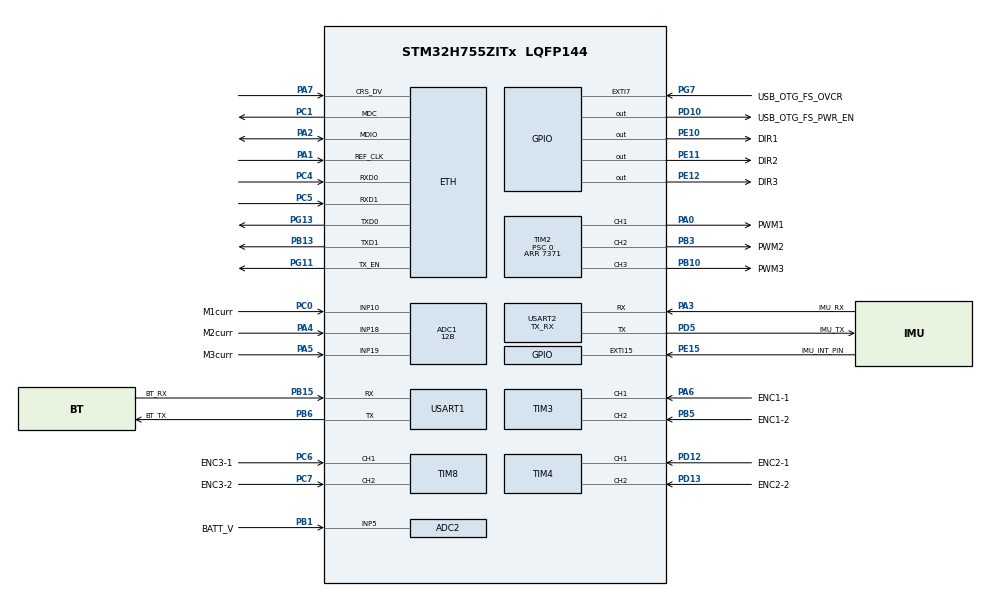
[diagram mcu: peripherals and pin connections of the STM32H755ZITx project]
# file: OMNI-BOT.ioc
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ADC1.Channel-1\#ChannelRegularConversion=ADC_CHANNEL_10
ADC1.Channel-2\#ChannelRegularConversion=ADC_CHANNEL_18
ADC1.Channel-3\#ChannelRegularConversion=ADC_CHANNEL_19
ADC1.ContinuousConvMode=DISABLE
ADC1.ExternalTrigConv=ADC_EXTERNALTRIG_T6_TRGO
ADC1.NbrOfConversion=3
ADC1.NbrOfConversionFlag=1
ADC1.OffsetNumber-1\#ChannelRegularConversion=ADC_OFFSET_NONE
ADC1.OffsetNumber-2\#ChannelRegularConversion=ADC_OFFSET_NONE
ADC1.OffsetNumber-3\#ChannelRegularConversion=ADC_OFFSET_NONE
ADC1.OffsetSignedSaturation-1\#ChannelRegularConversion=DISABLE
ADC1.OffsetSignedSaturation-2\#ChannelRegularConversion=DISABLE
ADC1.OffsetSignedSaturation-3\#ChannelRegularConversion=DISABLE
ADC1.Overrun=ADC_OVR_DATA_OVERWRITTEN
ADC1.Rank-1\#ChannelRegularConversion=1
ADC1.Rank-2\#ChannelRegularConversion=2
ADC1.Rank-3\#ChannelRegularConversion=3
ADC1.Resolution=ADC_RESOLUTION_12B
ADC1.SamplingTime-1\#ChannelRegularConversion=ADC_SAMPLETIME_64CYCLES_5
ADC1.SamplingTime-2\#ChannelRegularConversion=ADC_SAMPLETIME_64CYCLES_5
ADC1.SamplingTime-3\#ChannelRegularConversion=ADC_SAMPLETIME_64CYCLES_5
ADC1.master=1
ADC2.Channel-1\#ChannelRegularConversion=ADC_CHANNEL_5
ADC2.NbrOfConversionFlag=1
ADC2.OffsetNumber-1\#ChannelRegularConversion=ADC_OFFSET_NONE
ADC2.OffsetSignedSaturation-1\#ChannelRegularConversion=DISABLE
ADC2.Rank-1\#ChannelRegularConversion=1
ADC2.SamplingTime-1\#ChannelRegularConversion=ADC_SAMPLETIME_64CYCLES_5
CortexM4.IPs=FATFS_M4\:I,FREERTOS_M4\:I,IWDG2\:I,RCC,WWDG2\:I,DMA,BDMA,MDMA,NVIC2\:I,ETH,USART3,DEBUG,PDM2PCM_M4\:I,PWR,RESMGR_UTILITY,SYS_M4\:I,USB_DEVICE_M4\:I,USB_HOST_M4\:I,CORTEX_M4\:I,GPIO,OPENAMP_M4\:I,VREFBUF,NUCLEO-H755ZI-Q
CortexM7.IPs=FATFS_M7\:I,FREERTOS_M7\:I,IWDG1\:I,RCC\:I,WWDG1\:I,DMA\:I,BDMA\:I,MDMA\:I,NVIC1\:I,ETH\:I,USART3\:I,USB_OTG_FS\:I,SYS\:I,CORTEX_M7\:I,DEBUG\:I,PDM2PCM_M7\:I,PWR\:I,RESMGR_UTILITY\:I,USB_DEVICE_M7\:I,USB_HOST_M7\:I,GPIO\:I,OPENAMP_M7\:I,VREFBUF\:I,NUCLEO-H755ZI-Q\:I,TIM2\:I,TIM8\:I,TIM3\:I,TIM4\:I,USART2\:I,USART1\:I,LWIP\:I,ADC1\:I,ADC2\:I
CortexM7.Pins=PE15
Dma.ADC1.0.Direction=DMA_PERIPH_TO_MEMORY
Dma.ADC1.0.EventEnable=DISABLE
Dma.ADC1.0.FIFOMode=DMA_FIFOMODE_DISABLE
Dma.ADC1.0.Instance=DMA1_Stream0
Dma.ADC1.0.MemDataAlignment=DMA_MDATAALIGN_HALFWORD
Dma.ADC1.0.MemInc=DMA_MINC_ENABLE
Dma.ADC1.0.Mode=DMA_CIRCULAR
Dma.ADC1.0.PeriphDataAlignment=DMA_PDATAALIGN_HALFWORD
Dma.ADC1.0.PeriphInc=DMA_PINC_DISABLE
Dma.ADC1.0.Polarity=HAL_DMAMUX_REQ_GEN_RISING
Dma.ADC1.0.Priority=DMA_PRIORITY_LOW
Dma.ADC1.0.RequestNumber=1
Dma.ADC1.0.SignalID=NONE
Dma.ADC1.0.SyncEnable=DISABLE
Dma.ADC1.0.SyncPolarity=HAL_DMAMUX_SYNC_NO_EVENT
Dma.ADC1.0.SyncRequestNumber=1
Dma.ADC1.0.SyncSignalID=NONE
Dma.Request0=ADC1
ETH.MediaInterface=HAL_ETH_RMII_MODE
FREERTOS_M4.Tasks01=defaultTask,24,128,StartDefaultTask,Default,NULL,Dynamic,NULL,NULL
FREERTOS_M4.configENABLE_FPU=1
FREERTOS_M7.Tasks01=defaultTask,24,1024,StartDefaultTask,Default,NULL,Dynamic,NULL,NULL
FREERTOS_M7.configENABLE_FPU=1
FREERTOS_M7.configTOTAL_HEAP_SIZE=98304
LWIP.BSP.number=1
LWIP.GATEWAY_ADDRESS=192.168.001.001
LWIP.IP_ADDRESS=192.168.001.010
LWIP.LWIP_DHCP=0
LWIP.LWIP_TCP=0
LWIP.NETMASK_ADDRESS=255.255.255.000
LWIP.Version=v2.1.2_Cube
LWIP0.BSP.STBoard=false
LWIP0.BSP.api=BSP_COMPONENT_DRIVER
LWIP0.BSP.component=LAN8742
LWIP0.BSP.instance=LAN8742
LWIP0.BSP.name=Driver_PHY
LWIP0.BSP.semaphore=S_LAN8742
LWIP0.BSP.solution=LAN8742
Mcu.Family=STM32H7
Mcu.Name=STM32H755ZITx
Mcu.Package=LQFP144
NUCLEO-H755ZI-Q.BUTTON=1
NUCLEO-H755ZI-Q.LD1=true
NUCLEO-H755ZI-Q.LD2=true
NUCLEO-H755ZI-Q.LD3=true
NUCLEO-H755ZI-Q.VCP=true
NVIC1.DMA1_Stream0_IRQn=true\:5\:0\:false\:false\:true\:true\:false\:true\:true
NVIC1.ETH_IRQn=true\:5\:0\:false\:false\:true\:true\:true\:true\:true
NVIC1.EXTI15_10_IRQn=true\:5\:0\:false\:false\:true\:true\:false\:true\:true
NVIC1.PriorityGroup=NVIC_PRIORITYGROUP_4
NVIC1.USART1_IRQn=true\:5\:0\:false\:false\:true\:true\:true\:true\:true
NVIC1.USART2_IRQn=true\:5\:0\:false\:false\:true\:true\:true\:true\:true
NVIC2.PriorityGroup=NVIC_PRIORITYGROUP_4
PA0.GPIO_Label=PWM1
PA0.PinAttribute=CortexM7
PA0.Signal=S_TIM2_CH1_ETR
PA1.Mode=RMII
PA1.PinAttribute=CortexM7
PA1.Signal=ETH_REF_CLK
PA11.PinAttribute=CortexM7
PA11.Signal=USB_OTG_FS_DM
PA12.PinAttribute=CortexM7
PA12.Signal=USB_OTG_FS_DP
PA2.Mode=RMII
PA2.PinAttribute=CortexM7
PA2.Signal=ETH_MDIO
PA3.GPIO_Label=IMU_RX
PA3.Mode=Asynchronous
PA3.PinAttribute=CortexM7
PA3.Signal=USART2_RX
PA4.GPIO_Label=M2curr
PA4.PinAttribute=CortexM7
PA4.Signal=ADCx_INP18
PA5.GPIO_Label=M3curr
PA5.PinAttribute=CortexM7
PA5.Signal=ADCx_INP19
PA6.GPIO_Label=ENC1-1
PA6.PinAttribute=CortexM7
PA6.Signal=S_TIM3_CH1
PA7.Mode=RMII
PA7.PinAttribute=CortexM7
PA7.Signal=ETH_CRS_DV
PA8.PinAttribute=CortexM7
PA8.Signal=USB_OTG_FS_SOF
PA9.PinAttribute=CortexM7
PA9.Signal=USB_OTG_FS_VBUS
PB1.GPIO_Label=BATT_V
PB1.PinAttribute=CortexM7
PB1.Signal=ADCx_INP5
PB10.GPIO_Label=PWM3
PB10.PinAttribute=CortexM7
PB10.Signal=S_TIM2_CH3
PB13.Mode=RMII
PB13.PinAttribute=CortexM7
PB13.Signal=ETH_TXD1
PB15.GPIO_Label=BT_RX
PB15.Mode=Asynchronous
PB15.PinAttribute=CortexM7
PB15.Signal=USART1_RX
PB3\ (JTDO/TRACESWO).GPIO_Label=PWM2
PB3\ (JTDO/TRACESWO).PinAttribute=CortexM7
PB3\ (JTDO/TRACESWO).Signal=S_TIM2_CH2
PB5.GPIO_Label=ENC1-2
PB5.PinAttribute=CortexM7
PB5.Signal=S_TIM3_CH2
PB6.GPIO_Label=BT_TX
PB6.Mode=Asynchronous
PB6.PinAttribute=CortexM7
PB6.Signal=USART1_TX
PC0.GPIO_Label=M1curr
PC0.PinAttribute=CortexM7
PC0.Signal=ADCx_INP10
PC1.Mode=RMII
PC1.PinAttribute=CortexM7
PC1.Signal=ETH_MDC
PC14-OSC32_IN\ (OSC32_IN).PinAttribute=Free
PC14-OSC32_IN\ (OSC32_IN).Signal=RCC_OSC32_IN
PC15-OSC32_OUT\ (OSC32_OUT).PinAttribute=Free
PC15-OSC32_OUT\ (OSC32_OUT).Signal=RCC_OSC32_OUT
PC4.Mode=RMII
PC4.PinAttribute=CortexM7
PC4.Signal=ETH_RXD0
PC5.Mode=RMII
PC5.PinAttribute=CortexM7
PC5.Signal=ETH_RXD1
PC6.GPIO_Label=ENC3-1
PC6.PinAttribute=CortexM7
PC6.Signal=S_TIM8_CH1
PC7.GPIO_Label=ENC3-2
PC7.PinAttribute=CortexM7
PC7.Signal=S_TIM8_CH2
PD10.GPIO_Label=USB_OTG_FS_PWR_EN
PD10.PinAttribute=Free
PD10.Signal=GPIO_Output
PD12.GPIO_Label=ENC2-1
PD12.PinAttribute=CortexM7
PD12.Signal=S_TIM4_CH1
PD13.GPIO_Label=ENC2-2
PD13.PinAttribute=CortexM7
PD13.Signal=S_TIM4_CH2
PD5.GPIO_Label=IMU_TX
PD5.Mode=Asynchronous
PD5.PinAttribute=CortexM7
PD5.Signal=USART2_TX
PD8.Signal=USART3_TX
PD9.Signal=USART3_RX
PE10.GPIO_Label=DIR1
PE10.PinAttribute=Free
PE10.Signal=GPIO_Output
PE11.GPIO_Label=DIR2
PE11.PinAttribute=Free
PE11.Signal=GPIO_Output
PE12.GPIO_Label=DIR3
PE12.PinAttribute=Free
PE12.Signal=GPIO_Output
PE15.GPIO_Label=IMU_INT_PIN
PE15.GPIO_ModeDefaultEXTI=GPIO_MODE_IT_FALLING
PE15.GPIO_PuPd=GPIO_PULLUP
PE15.PinAttribute=CortexM7
PE15.Signal=GPXTI15
PG11.Mode=RMII
PG11.PinAttribute=CortexM7
PG11.Signal=ETH_TX_EN
PG13.Mode=RMII
PG13.PinAttribute=CortexM7
PG13.Signal=ETH_TXD0
PG7.GPIO_Label=USB_OTG_FS_OVCR
PG7.PinAttribute=Free
PG7.Signal=GPXTI7
PH0-OSC_IN\ (PH0).PinAttribute=Free
PH0-OSC_IN\ (PH0).Signal=RCC_OSC_IN
PH1-OSC_OUT\ (PH1).PinAttribute=Free
PH1-OSC_OUT\ (PH1).Signal=RCC_OSC_OUT
ProjectManager.HeapSize=M4-0x200,M7-0x200
ProjectManager.StackSize=M4-0x400,M7-0x400
ProjectManager.TargetToolchain=Makefile
RCC.ADCCLockSelection=RCC_ADCCLKSOURCE_CLKP
RCC.ADCFreq_Value=64000000
RCC.APB1Freq_Value=73600000
RCC.APB2Freq_Value=73600000
RCC.APB3Freq_Value=73600000
RCC.APB4Freq_Value=73600000
RCC.CortexFreq_Value=294400000
RCC.D1PPRE=RCC_APB3_DIV2
RCC.D2PPRE1=RCC_APB1_DIV2
RCC.D2PPRE2=RCC_APB2_DIV2
RCC.D3PPRE=RCC_APB4_DIV2
RCC.DIVM1=5
RCC.DIVN1=46
RCC.DIVQ1=5
RCC.HCLKFreq_Value=147200000
RCC.HPRE=RCC_HCLK_DIV2
RCC.SYSCLKFreq_VALUE=294400000
RCC.SYSCLKSource=RCC_SYSCLKSOURCE_PLLCLK
RCC.SupplySource=PWR_DIRECT_SMPS_SUPPLY
RCC.USBFreq_Value=117760000
SH.ADCx_INP10.0=ADC1_INP10,IN10-Single-Ended
SH.ADCx_INP18.0=ADC1_INP18,IN18-Single-Ended
SH.ADCx_INP19.0=ADC1_INP19,IN19-Single-Ended
SH.ADCx_INP5.0=ADC2_INP5,IN5-Single-Ended
SH.S_TIM2_CH1_ETR.0=TIM2_CH1,PWM Generation1 CH1
SH.S_TIM2_CH2.0=TIM2_CH2,PWM Generation2 CH2
SH.S_TIM2_CH3.0=TIM2_CH3,PWM Generation3 CH3
SH.S_TIM3_CH1.0=TIM3_CH1,Encoder_Interface
SH.S_TIM3_CH2.0=TIM3_CH2,Encoder_Interface
SH.S_TIM4_CH1.0=TIM4_CH1,Encoder_Interface
SH.S_TIM4_CH2.0=TIM4_CH2,Encoder_Interface
SH.S_TIM8_CH1.0=TIM8_CH1,Encoder_Interface
SH.S_TIM8_CH2.0=TIM8_CH2,Encoder_Interface
TIM2.AutoReloadPreload=TIM_AUTORELOAD_PRELOAD_ENABLE
TIM2.Channel-PWM\ Generation1\ CH1=TIM_CHANNEL_1
TIM2.Channel-PWM\ Generation2\ CH2=TIM_CHANNEL_2
TIM2.Channel-PWM\ Generation3\ CH3=TIM_CHANNEL_3
TIM2.Period=7371
TIM2.Prescaler=0
TIM3.EncoderMode=TIM_ENCODERMODE_TI12
TIM3.IC1Filter=8
TIM3.IC2Filter=8
TIM4.EncoderMode=TIM_ENCODERMODE_TI12
TIM4.IC1Filter=8
TIM4.IC2Filter=8
TIM8.EncoderMode=TIM_ENCODERMODE_TI12
TIM8.IC1Filter=8
TIM8.IC2Filter=8
USART1.VirtualMode-Asynchronous=VM_ASYNC
USART2.Mode=MODE_TX_RX
USART2.VirtualMode-Asynchronous=VM_ASYNC
VP_FREERTOS_M4_VS_CMSIS_V2.Mode=CMSIS_V2
VP_FREERTOS_M7_VS_CMSIS_V2.Mode=CMSIS_V2
VP_LWIP_VS_Enabled.Mode=Enabled
VP_NUCLEO-H755ZI-Q_VS_BSP_COMMON.Mode=COMMON
VP_SYS_M4_VS_Systick.Mode=SysTick
board=NUCLEO-H755ZI-Q

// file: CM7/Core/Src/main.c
/* USER CODE BEGIN Header */
/**
  ******************************************************************************
  * @file           : main.c
  * @brief          : Main program body
  ******************************************************************************
  * @attention
  *
  * Copyright (c) 2025 STMicroelectronics.
  * All rights reserved.
  *
  * This software is licensed under terms that can be found in the LICENSE file
  * in the root directory of this software component.
  * If no LICENSE file comes with this software, it is provided AS-IS.
  *
  ******************************************************************************
  */
/* USER CODE END Header */
#include "main.h"
#include "cmsis_os.h"
#include "lwip.h"

/* USER CODE BEGIN Includes */
#include "controller.h"
#include "sensor.h"
#include <stdio.h>
#include "cmd.h"
#include "IMU.h"
#include "udp_client.h"
#include "battery_monitor.h"
/* USER CODE END Includes */

/* USER CODE BEGIN PTD */
// Omni geometry (180 mm wheel diameter => 0.09 m radius)
double rw = 0.09;        // wheel radius (m)
double L = 0.2;          // distance from robot center to wheel contact line (m)
static const double CPR = SATURN5303_OUTPUT_CPR;
const int32_t CNT_MID = 32768;  // 0x8000
/* USER CODE END PTD */

/* USER CODE BEGIN PD */

/* DUAL_CORE_BOOT_SYNC_SEQUENCE: Define for dual core boot synchronization    */
/*                             demonstration code based on hardware semaphore */
/* This define is present in both CM7/CM4 projects                            */
/* To comment when developping/debugging on a single core                     */
#define DUAL_CORE_BOOT_SYNC_SEQUENCE

#if defined(DUAL_CORE_BOOT_SYNC_SEQUENCE)
#ifndef HSEM_ID_0
#define HSEM_ID_0 (0U) /* HW semaphore 0*/
#endif
#endif /* DUAL_CORE_BOOT_SYNC_SEQUENCE */

/* USER CODE END PD */

/* USER CODE BEGIN PM */
double const pion180 = 0.01745329251;
/* USER CODE END PM */

COM_InitTypeDef BspCOMInit;
ADC_HandleTypeDef hadc1;
ADC_HandleTypeDef hadc2;
DMA_HandleTypeDef hdma_adc1;

TIM_HandleTypeDef htim2;
TIM_HandleTypeDef htim3;
TIM_HandleTypeDef htim4;
TIM_HandleTypeDef htim8;

UART_HandleTypeDef huart1;
UART_HandleTypeDef huart2;

/* Definitions for defaultTask */
osThreadId_t defaultTaskHandle;
const osThreadAttr_t defaultTask_attributes = {
  .name = "defaultTask",
  .stack_size = 1024 * 4,
  .priority = (osPriority_t) osPriorityNormal,
};
/* USER CODE BEGIN PV */

static TIM_HandleTypeDef htim6;

osThreadId_t control_id;
const osThreadAttr_t control_att = {
  .name = "control_t",
  .stack_size = 1028*8,
  .priority = (osPriority_t) osPriorityNormal,
};
osThreadId_t remote_id;
const osThreadAttr_t remote_att = {
  .name = "remote_t",
  .stack_size = 1028*6,  // Reduced from 8224 to 6168 to save heap - main loop needs ~2-3KB
  .priority = (osPriority_t) osPriorityNormal,
};
osThreadId_t ethernet_id;
const osThreadAttr_t ethernet_att = {
  .name = "ethernet_t",
  .stack_size = 1024 * 8,
  .priority = (osPriority_t) osPriorityLow,
};

#define MOTOR_CURRENT_DMA_CHANNELS   3u
#define MOTOR_CURRENT_DMA_SEQUENCES  32u
#define MOTOR_CURRENT_DMA_SAMPLES    (MOTOR_CURRENT_DMA_CHANNELS * MOTOR_CURRENT_DMA_SEQUENCES)
static uint16_t s_motorCurrentAdcDmaBuf[MOTOR_CURRENT_DMA_SAMPLES] = {0u};
static uint8_t s_motorCurrentDmaStarted = 0u;
/* USER CODE END PV */

void SystemClock_Config(void);
void PeriphCommonClock_Config(void);
static void MX_GPIO_Init(void);
static void MX_DMA_Init(void);
static void MX_USART1_UART_Init(void);
static void MX_TIM2_Init(void);
static void MX_TIM4_Init(void);
static void MX_TIM8_Init(void);
static void MX_TIM3_Init(void);
static void MX_USART2_UART_Init(void);
static void MX_ADC1_Init(void);
static void MX_ADC2_Init(void);
void StartDefaultTask(void *argument);

/* USER CODE BEGIN PFP */
void control(void *argument);
void remote(void *argument);
/* USER CODE END PFP */

/* USER CODE BEGIN 0 */
static uint8_t rx1_byte;
static uint8_t rx2_byte;

static void TIM6_User_Init(void)
{
  TIM_MasterConfigTypeDef sMasterConfig = {0};

  htim6.Instance = TIM6;
  htim6.Init.Prescaler = 274;
  htim6.Init.Period = 99;
  htim6.Init.AutoReloadPreload = TIM_AUTORELOAD_PRELOAD_DISABLE;
  if (HAL_TIM_Base_Init(&htim6) != HAL_OK)
  {
    Error_Handler();
  }

  sMasterConfig.MasterOutputTrigger = TIM_TRGO_UPDATE;
  sMasterConfig.MasterSlaveMode = TIM_MASTERSLAVEMODE_DISABLE;
  if (HAL_TIMEx_MasterConfigSynchronization(&htim6, &sMasterConfig) != HAL_OK)
  {
    Error_Handler();
  }
}

static void UartRearmRxIt(UART_HandleTypeDef *huart, uint8_t *byte)
{
  if ((huart == NULL) || (byte == NULL))
  {
    return;
  }

  if (HAL_UART_Receive_IT(huart, byte, 1) != HAL_OK)
  {
    (void)HAL_UART_AbortReceive(huart);
    (void)HAL_UART_Receive_IT(huart, byte, 1);
  }
}

void UartStartRx(void)
{
  UartRearmRxIt(&huart1, &rx1_byte);
  UartRearmRxIt(&huart2, &rx2_byte);
}

void HAL_UART_RxCpltCallback(UART_HandleTypeDef *huart)
{
  if (huart == &huart1)
  {
    CMD_OnUartRxByteFromISR(rx1_byte);
    UartRearmRxIt(&huart1, &rx1_byte);
  }
  else if (huart == &huart2)
  {
    BNO_RVC_OnByte(rx2_byte);
    UartRearmRxIt(&huart2, &rx2_byte);
  }
}

void HAL_UART_ErrorCallback(UART_HandleTypeDef *huart)
{
  if (huart == &huart1)
  {
    UartRearmRxIt(&huart1, &rx1_byte);
  }
  else if (huart == &huart2)
  {
    UartRearmRxIt(&huart2, &rx2_byte);
  }
}
void TIM_init(void)
{
// Initialize MD20A motor drivers: 0% duty cycle and forward direction
__HAL_TIM_SET_COMPARE(&htim2, TIM_CHANNEL_1, 0);
__HAL_TIM_SET_COMPARE(&htim2, TIM_CHANNEL_2, 0);
__HAL_TIM_SET_COMPARE(&htim2, TIM_CHANNEL_3, 0);

// Set all direction pins to forward (LOW)
HAL_GPIO_WritePin(DIR1_GPIO_Port, DIR1_Pin, GPIO_PIN_RESET);
HAL_GPIO_WritePin(DIR2_GPIO_Port, DIR2_Pin, GPIO_PIN_RESET);
HAL_GPIO_WritePin(DIR3_GPIO_Port, DIR3_Pin, GPIO_PIN_RESET);

HAL_TIM_PWM_Start(&htim2, TIM_CHANNEL_1);
HAL_TIM_PWM_Start(&htim2, TIM_CHANNEL_2);
HAL_TIM_PWM_Start(&htim2, TIM_CHANNEL_3);

HAL_TIM_Encoder_Start(&htim3, TIM_CHANNEL_ALL);
	__HAL_TIM_SET_COUNTER(&htim3, CNT_MID);
HAL_TIM_Encoder_Start(&htim4, TIM_CHANNEL_ALL);
	__HAL_TIM_SET_COUNTER(&htim4, CNT_MID);
HAL_TIM_Encoder_Start(&htim8, TIM_CHANNEL_ALL);
	__HAL_TIM_SET_COUNTER(&htim8, CNT_MID);
}
/* USER CODE END 0 */

int main(void)
{

/* USER CODE BEGIN Boot_Mode_Sequence_0 */
#if defined(DUAL_CORE_BOOT_SYNC_SEQUENCE)
  int32_t timeout;
#endif /* DUAL_CORE_BOOT_SYNC_SEQUENCE */
/* USER CODE END Boot_Mode_Sequence_0 */

/* USER CODE BEGIN Boot_Mode_Sequence_1 */
#if defined(DUAL_CORE_BOOT_SYNC_SEQUENCE)
  /* Wait until CPU2 boots and enters in stop mode or timeout*/
  timeout = 0xFFFF;
  while((__HAL_RCC_GET_FLAG(RCC_FLAG_D2CKRDY) != RESET) && (timeout-- > 0));
  if ( timeout < 0 )
  {
  Error_Handler();
  }
#endif /* DUAL_CORE_BOOT_SYNC_SEQUENCE */
/* USER CODE END Boot_Mode_Sequence_1 */
  /* MCU Configuration--------------------------------------------------------*/

  /* Reset of all peripherals, Initializes the Flash interface and the Systick. */
  HAL_Init();

  /* Configure the system clock */
  SystemClock_Config();

  /* Configure the peripherals common clocks */
  PeriphCommonClock_Config();
/* USER CODE BEGIN Boot_Mode_Sequence_2 */
#if defined(DUAL_CORE_BOOT_SYNC_SEQUENCE)
/* When system initialization is finished, Cortex-M7 will release Cortex-M4 by means of
HSEM notification */
/*HW semaphore Clock enable*/
__HAL_RCC_HSEM_CLK_ENABLE();
/*Take HSEM */
HAL_HSEM_FastTake(HSEM_ID_0);
/*Release HSEM in order to notify the CPU2(CM4)*/
HAL_HSEM_Release(HSEM_ID_0,0);
/* wait until CPU2 wakes up from stop mode */
timeout = 0xFFFF;
while((__HAL_RCC_GET_FLAG(RCC_FLAG_D2CKRDY) == RESET) && (timeout-- > 0));
if ( timeout < 0 )
{
Error_Handler();
}
#endif /* DUAL_CORE_BOOT_SYNC_SEQUENCE */
/* USER CODE END Boot_Mode_Sequence_2 */

  /* Initialize all configured peripherals */
  MX_GPIO_Init();
  MX_DMA_Init();
  MX_USART1_UART_Init();
  MX_TIM2_Init();
  MX_TIM4_Init();
  MX_TIM8_Init();
  MX_TIM3_Init();
  MX_USART2_UART_Init();
  MX_ADC1_Init();
  MX_ADC2_Init();
  /* USER CODE BEGIN 2 */
  TIM6_User_Init();
  BatteryMonitor_Init();
  if (HAL_ADC_Start_DMA(&hadc1, (uint32_t *)s_motorCurrentAdcDmaBuf, MOTOR_CURRENT_DMA_SAMPLES) != HAL_OK)
  {
    Error_Handler();
  }
  if (HAL_TIM_Base_Start(&htim6) != HAL_OK)
  {
    Error_Handler();
  }
  s_motorCurrentDmaStarted = 1u;
  CMD_Init(&huart1);
  BNO_RVC_Init();
  UartStartRx();
  TIM_init();
  /* USER CODE END 2 */

  /* Init scheduler */
  osKernelInitialize();

  /* Create the thread(s) */
  /* creation of defaultTask */
  defaultTaskHandle = osThreadNew(StartDefaultTask, NULL, &defaultTask_attributes);

  /* USER CODE BEGIN RTOS_THREADS */
  CMD_StartTask();
  remote_id = osThreadNew(remote, NULL, &remote_att);
  ethernet_id = osThreadNew(UDP_Client_Task, NULL, &ethernet_att);
  //control_id = osThreadNew(control, NULL, &control_att);
  //imu_id = osThreadNew(imu_task, NULL, &imu_att);

  /* USER CODE END RTOS_THREADS */

  /* Initialize leds */
  BSP_LED_Init(LED_GREEN);
  BSP_LED_Init(LED_YELLOW);
  BSP_LED_Init(LED_RED);

  /* Initialize USER push-button, will be used to trigger an interrupt each time it's pressed.*/
  BSP_PB_Init(BUTTON_USER, BUTTON_MODE_EXTI);

  /* Initialize COM1 port (115200, 8 bits (7-bit data + 1 stop bit), no parity */
  BspCOMInit.BaudRate   = 115200;
  BspCOMInit.WordLength = COM_WORDLENGTH_8B;
  BspCOMInit.StopBits   = COM_STOPBITS_1;
  BspCOMInit.Parity     = COM_PARITY_NONE;
  BspCOMInit.HwFlowCtl  = COM_HWCONTROL_NONE;
  if (BSP_COM_Init(COM1, &BspCOMInit) != BSP_ERROR_NONE)
  {
    Error_Handler();
  }

  /* Start scheduler */
  osKernelStart();

  /* We should never get here as control is now taken by the scheduler */

  /* Infinite loop */
  while (1)
  {

  }
}

void SystemClock_Config(void)
{
  RCC_OscInitTypeDef RCC_OscInitStruct = {0};
  RCC_ClkInitTypeDef RCC_ClkInitStruct = {0};

  /** Supply configuration update enable
  */
  HAL_PWREx_ConfigSupply(PWR_DIRECT_SMPS_SUPPLY);

  /** Configure the main internal regulator output voltage
  */
  __HAL_PWR_VOLTAGESCALING_CONFIG(PWR_REGULATOR_VOLTAGE_SCALE2);

  while(!__HAL_PWR_GET_FLAG(PWR_FLAG_VOSRDY)) {}

  /** Initializes the RCC Oscillators according to the specified parameters
  * in the RCC_OscInitTypeDef structure.
  */
  RCC_OscInitStruct.OscillatorType = RCC_OSCILLATORTYPE_HSI;
  RCC_OscInitStruct.HSIState = RCC_HSI_DIV1;
  RCC_OscInitStruct.HSICalibrationValue = RCC_HSICALIBRATION_DEFAULT;
  RCC_OscInitStruct.PLL.PLLState = RCC_PLL_ON;
  RCC_OscInitStruct.PLL.PLLSource = RCC_PLLSOURCE_HSI;
  RCC_OscInitStruct.PLL.PLLM = 5;
  RCC_OscInitStruct.PLL.PLLN = 46;
  RCC_OscInitStruct.PLL.PLLP = 2;
  RCC_OscInitStruct.PLL.PLLQ = 5;
  RCC_OscInitStruct.PLL.PLLR = 2;
  RCC_OscInitStruct.PLL.PLLRGE = RCC_PLL1VCIRANGE_3;
  RCC_OscInitStruct.PLL.PLLVCOSEL = RCC_PLL1VCOWIDE;
  RCC_OscInitStruct.PLL.PLLFRACN = 0;
  if (HAL_RCC_OscConfig(&RCC_OscInitStruct) != HAL_OK)
  {
    Error_Handler();
  }

  /** Initializes the CPU, AHB and APB buses clocks
  */
  RCC_ClkInitStruct.ClockType = RCC_CLOCKTYPE_HCLK|RCC_CLOCKTYPE_SYSCLK
                              |RCC_CLOCKTYPE_PCLK1|RCC_CLOCKTYPE_PCLK2
                              |RCC_CLOCKTYPE_D3PCLK1|RCC_CLOCKTYPE_D1PCLK1;
  RCC_ClkInitStruct.SYSCLKSource = RCC_SYSCLKSOURCE_PLLCLK;
  RCC_ClkInitStruct.SYSCLKDivider = RCC_SYSCLK_DIV1;
  RCC_ClkInitStruct.AHBCLKDivider = RCC_HCLK_DIV2;
  RCC_ClkInitStruct.APB3CLKDivider = RCC_APB3_DIV2;
  RCC_ClkInitStruct.APB1CLKDivider = RCC_APB1_DIV2;
  RCC_ClkInitStruct.APB2CLKDivider = RCC_APB2_DIV2;
  RCC_ClkInitStruct.APB4CLKDivider = RCC_APB4_DIV2;

  if (HAL_RCC_ClockConfig(&RCC_ClkInitStruct, FLASH_LATENCY_2) != HAL_OK)
  {
    Error_Handler();
  }
}

void PeriphCommonClock_Config(void)
{
  RCC_PeriphCLKInitTypeDef PeriphClkInitStruct = {0};

  /** Initializes the peripherals clock
  */
  PeriphClkInitStruct.PeriphClockSelection = RCC_PERIPHCLK_CKPER;
  PeriphClkInitStruct.CkperClockSelection = RCC_CLKPSOURCE_HSI;
  if (HAL_RCCEx_PeriphCLKConfig(&PeriphClkInitStruct) != HAL_OK)
  {
    Error_Handler();
  }
}

static void MX_ADC1_Init(void)
{

  ADC_MultiModeTypeDef multimode = {0};
  ADC_ChannelConfTypeDef sConfig = {0};

  /** Common config
  */
  hadc1.Instance = ADC1;
  hadc1.Init.ClockPrescaler = ADC_CLOCK_ASYNC_DIV2;
  hadc1.Init.Resolution = ADC_RESOLUTION_12B;
  hadc1.Init.ScanConvMode = ADC_SCAN_ENABLE;
  hadc1.Init.EOCSelection = ADC_EOC_SINGLE_CONV;
  hadc1.Init.LowPowerAutoWait = DISABLE;
  hadc1.Init.ContinuousConvMode = DISABLE;
  hadc1.Init.NbrOfConversion = 3;
  hadc1.Init.DiscontinuousConvMode = DISABLE;
  hadc1.Init.ExternalTrigConv = ADC_EXTERNALTRIG_T6_TRGO;
  hadc1.Init.ExternalTrigConvEdge = ADC_EXTERNALTRIGCONVEDGE_RISING;
  hadc1.Init.ConversionDataManagement = ADC_CONVERSIONDATA_DMA_CIRCULAR;
  hadc1.Init.Overrun = ADC_OVR_DATA_OVERWRITTEN;
  hadc1.Init.LeftBitShift = ADC_LEFTBITSHIFT_NONE;
  hadc1.Init.OversamplingMode = DISABLE;
  hadc1.Init.Oversampling.Ratio = 1;
  if (HAL_ADC_Init(&hadc1) != HAL_OK)
  {
    Error_Handler();
  }

  /** Configure the ADC multi-mode
  */
  multimode.Mode = ADC_MODE_INDEPENDENT;
  if (HAL_ADCEx_MultiModeConfigChannel(&hadc1, &multimode) != HAL_OK)
  {
    Error_Handler();
  }

  /** Configure Regular Channel
  */
  sConfig.Channel = ADC_CHANNEL_10;
  sConfig.Rank = ADC_REGULAR_RANK_1;
  sConfig.SamplingTime = ADC_SAMPLETIME_64CYCLES_5;
  sConfig.SingleDiff = ADC_SINGLE_ENDED;
  sConfig.OffsetNumber = ADC_OFFSET_NONE;
  sConfig.Offset = 0;
  sConfig.OffsetSignedSaturation = DISABLE;
  if (HAL_ADC_ConfigChannel(&hadc1, &sConfig) != HAL_OK)
  {
    Error_Handler();
  }

  /** Configure Regular Channel
  */
  sConfig.Channel = ADC_CHANNEL_18;
  sConfig.Rank = ADC_REGULAR_RANK_2;
  if (HAL_ADC_ConfigChannel(&hadc1, &sConfig) != HAL_OK)
  {
    Error_Handler();
  }

  /** Configure Regular Channel
  */
  sConfig.Channel = ADC_CHANNEL_19;
  sConfig.Rank = ADC_REGULAR_RANK_3;
  if (HAL_ADC_ConfigChannel(&hadc1, &sConfig) != HAL_OK)
  {
    Error_Handler();
  }

}

static void MX_ADC2_Init(void)
{

  ADC_ChannelConfTypeDef sConfig = {0};

  /** Common config
  */
  hadc2.Instance = ADC2;
  hadc2.Init.ClockPrescaler = ADC_CLOCK_ASYNC_DIV2;
  hadc2.Init.Resolution = ADC_RESOLUTION_16B;
  hadc2.Init.ScanConvMode = ADC_SCAN_DISABLE;
  hadc2.Init.EOCSelection = ADC_EOC_SINGLE_CONV;
  hadc2.Init.LowPowerAutoWait = DISABLE;
  hadc2.Init.ContinuousConvMode = DISABLE;
  hadc2.Init.NbrOfConversion = 1;
  hadc2.Init.DiscontinuousConvMode = DISABLE;
  hadc2.Init.ExternalTrigConv = ADC_SOFTWARE_START;
  hadc2.Init.ExternalTrigConvEdge = ADC_EXTERNALTRIGCONVEDGE_NONE;
  hadc2.Init.ConversionDataManagement = ADC_CONVERSIONDATA_DR;
  hadc2.Init.Overrun = ADC_OVR_DATA_PRESERVED;
  hadc2.Init.LeftBitShift = ADC_LEFTBITSHIFT_NONE;
  hadc2.Init.OversamplingMode = DISABLE;
  hadc2.Init.Oversampling.Ratio = 1;
  if (HAL_ADC_Init(&hadc2) != HAL_OK)
  {
    Error_Handler();
  }

  /** Configure Regular Channel
  */
  sConfig.Channel = ADC_CHANNEL_5;
  sConfig.Rank = ADC_REGULAR_RANK_1;
  sConfig.SamplingTime = ADC_SAMPLETIME_64CYCLES_5;
  sConfig.SingleDiff = ADC_SINGLE_ENDED;
  sConfig.OffsetNumber = ADC_OFFSET_NONE;
  sConfig.Offset = 0;
  sConfig.OffsetSignedSaturation = DISABLE;
  if (HAL_ADC_ConfigChannel(&hadc2, &sConfig) != HAL_OK)
  {
    Error_Handler();
  }

}

static void MX_TIM2_Init(void)
{

  TIM_MasterConfigTypeDef sMasterConfig = {0};
  TIM_OC_InitTypeDef sConfigOC = {0};

  htim2.Instance = TIM2;
  htim2.Init.Prescaler = 0;
  htim2.Init.CounterMode = TIM_COUNTERMODE_UP;
  htim2.Init.Period = 7371;
  htim2.Init.ClockDivision = TIM_CLOCKDIVISION_DIV1;
  htim2.Init.AutoReloadPreload = TIM_AUTORELOAD_PRELOAD_ENABLE;
  if (HAL_TIM_PWM_Init(&htim2) != HAL_OK)
  {
    Error_Handler();
  }
  sMasterConfig.MasterOutputTrigger = TIM_TRGO_RESET;
  sMasterConfig.MasterSlaveMode = TIM_MASTERSLAVEMODE_DISABLE;
  if (HAL_TIMEx_MasterConfigSynchronization(&htim2, &sMasterConfig) != HAL_OK)
  {
    Error_Handler();
  }
  sConfigOC.OCMode = TIM_OCMODE_PWM1;
  sConfigOC.Pulse = 0;
  sConfigOC.OCPolarity = TIM_OCPOLARITY_HIGH;
  sConfigOC.OCFastMode = TIM_OCFAST_DISABLE;
  if (HAL_TIM_PWM_ConfigChannel(&htim2, &sConfigOC, TIM_CHANNEL_1) != HAL_OK)
  {
    Error_Handler();
  }
  if (HAL_TIM_PWM_ConfigChannel(&htim2, &sConfigOC, TIM_CHANNEL_2) != HAL_OK)
  {
    Error_Handler();
  }
  if (HAL_TIM_PWM_ConfigChannel(&htim2, &sConfigOC, TIM_CHANNEL_3) != HAL_OK)
  {
    Error_Handler();
  }
  HAL_TIM_MspPostInit(&htim2);

}

static void MX_TIM3_Init(void)
{

  TIM_Encoder_InitTypeDef sConfig = {0};
  TIM_MasterConfigTypeDef sMasterConfig = {0};

  htim3.Instance = TIM3;
  htim3.Init.Prescaler = 0;
  htim3.Init.CounterMode = TIM_COUNTERMODE_UP;
  htim3.Init.Period = 65535;
  htim3.Init.ClockDivision = TIM_CLOCKDIVISION_DIV1;
  htim3.Init.AutoReloadPreload = TIM_AUTORELOAD_PRELOAD_DISABLE;
  sConfig.EncoderMode = TIM_ENCODERMODE_TI12;
  sConfig.IC1Polarity = TIM_ICPOLARITY_RISING;
  sConfig.IC1Selection = TIM_ICSELECTION_DIRECTTI;
  sConfig.IC1Prescaler = TIM_ICPSC_DIV1;
  sConfig.IC1Filter = 4;
  sConfig.IC2Polarity = TIM_ICPOLARITY_RISING;
  sConfig.IC2Selection = TIM_ICSELECTION_DIRECTTI;
  sConfig.IC2Prescaler = TIM_ICPSC_DIV1;
  sConfig.IC2Filter = 4;
  if (HAL_TIM_Encoder_Init(&htim3, &sConfig) != HAL_OK)
  {
    Error_Handler();
  }
  sMasterConfig.MasterOutputTrigger = TIM_TRGO_RESET;
  sMasterConfig.MasterSlaveMode = TIM_MASTERSLAVEMODE_DISABLE;
  if (HAL_TIMEx_MasterConfigSynchronization(&htim3, &sMasterConfig) != HAL_OK)
  {
    Error_Handler();
  }

}

static void MX_TIM4_Init(void)
{

  TIM_Encoder_InitTypeDef sConfig = {0};
  TIM_MasterConfigTypeDef sMasterConfig = {0};

  htim4.Instance = TIM4;
  htim4.Init.Prescaler = 0;
  htim4.Init.CounterMode = TIM_COUNTERMODE_UP;
  htim4.Init.Period = 65535;
  htim4.Init.ClockDivision = TIM_CLOCKDIVISION_DIV1;
  htim4.Init.AutoReloadPreload = TIM_AUTORELOAD_PRELOAD_DISABLE;
  sConfig.EncoderMode = TIM_ENCODERMODE_TI12;
  sConfig.IC1Polarity = TIM_ICPOLARITY_RISING;
  sConfig.IC1Selection = TIM_ICSELECTION_DIRECTTI;
  sConfig.IC1Prescaler = TIM_ICPSC_DIV1;
  sConfig.IC1Filter = 4;
  sConfig.IC2Polarity = TIM_ICPOLARITY_RISING;
  sConfig.IC2Selection = TIM_ICSELECTION_DIRECTTI;
  sConfig.IC2Prescaler = TIM_ICPSC_DIV1;
  sConfig.IC2Filter = 4;
  if (HAL_TIM_Encoder_Init(&htim4, &sConfig) != HAL_OK)
  {
    Error_Handler();
  }
  sMasterConfig.MasterOutputTrigger = TIM_TRGO_RESET;
  sMasterConfig.MasterSlaveMode = TIM_MASTERSLAVEMODE_DISABLE;
  if (HAL_TIMEx_MasterConfigSynchronization(&htim4, &sMasterConfig) != HAL_OK)
  {
    Error_Handler();
  }

}

static void MX_TIM8_Init(void)
{

  TIM_Encoder_InitTypeDef sConfig = {0};
  TIM_MasterConfigTypeDef sMasterConfig = {0};

  htim8.Instance = TIM8;
  htim8.Init.Prescaler = 0;
  htim8.Init.CounterMode = TIM_COUNTERMODE_UP;
  htim8.Init.Period = 65535;
  htim8.Init.ClockDivision = TIM_CLOCKDIVISION_DIV1;
  htim8.Init.RepetitionCounter = 0;
  htim8.Init.AutoReloadPreload = TIM_AUTORELOAD_PRELOAD_DISABLE;
  sConfig.EncoderMode = TIM_ENCODERMODE_TI12;
  sConfig.IC1Polarity = TIM_ICPOLARITY_RISING;
  sConfig.IC1Selection = TIM_ICSELECTION_DIRECTTI;
  sConfig.IC1Prescaler = TIM_ICPSC_DIV1;
  sConfig.IC1Filter = 4;
  sConfig.IC2Polarity = TIM_ICPOLARITY_RISING;
  sConfig.IC2Selection = TIM_ICSELECTION_DIRECTTI;
  sConfig.IC2Prescaler = TIM_ICPSC_DIV1;
  sConfig.IC2Filter = 4;
  if (HAL_TIM_Encoder_Init(&htim8, &sConfig) != HAL_OK)
  {
    Error_Handler();
  }
  sMasterConfig.MasterOutputTrigger = TIM_TRGO_RESET;
  sMasterConfig.MasterOutputTrigger2 = TIM_TRGO2_RESET;
  sMasterConfig.MasterSlaveMode = TIM_MASTERSLAVEMODE_DISABLE;
  if (HAL_TIMEx_MasterConfigSynchronization(&htim8, &sMasterConfig) != HAL_OK)
  {
    Error_Handler();
  }

}

static void MX_USART1_UART_Init(void)
{

  huart1.Instance = USART1;
  huart1.Init.BaudRate = 115200;
  huart1.Init.WordLength = UART_WORDLENGTH_8B;
  huart1.Init.StopBits = UART_STOPBITS_1;
  huart1.Init.Parity = UART_PARITY_NONE;
  huart1.Init.Mode = UART_MODE_TX_RX;
  huart1.Init.HwFlowCtl = UART_HWCONTROL_NONE;
  huart1.Init.OverSampling = UART_OVERSAMPLING_16;
  huart1.Init.OneBitSampling = UART_ONE_BIT_SAMPLE_DISABLE;
  huart1.Init.ClockPrescaler = UART_PRESCALER_DIV1;
  huart1.AdvancedInit.AdvFeatureInit = UART_ADVFEATURE_NO_INIT;
  if (HAL_UART_Init(&huart1) != HAL_OK)
  {
    Error_Handler();
  }
  if (HAL_UARTEx_SetTxFifoThreshold(&huart1, UART_TXFIFO_THRESHOLD_1_8) != HAL_OK)
  {
    Error_Handler();
  }
  if (HAL_UARTEx_SetRxFifoThreshold(&huart1, UART_RXFIFO_THRESHOLD_1_8) != HAL_OK)
  {
    Error_Handler();
  }
  if (HAL_UARTEx_DisableFifoMode(&huart1) != HAL_OK)
  {
    Error_Handler();
  }

}

static void MX_USART2_UART_Init(void)
{

  huart2.Instance = USART2;
  huart2.Init.BaudRate = 115200;
  huart2.Init.WordLength = UART_WORDLENGTH_8B;
  huart2.Init.StopBits = UART_STOPBITS_1;
  huart2.Init.Parity = UART_PARITY_NONE;
  huart2.Init.Mode = UART_MODE_TX_RX;
  huart2.Init.HwFlowCtl = UART_HWCONTROL_NONE;
  huart2.Init.OverSampling = UART_OVERSAMPLING_16;
  huart2.Init.OneBitSampling = UART_ONE_BIT_SAMPLE_DISABLE;
  huart2.Init.ClockPrescaler = UART_PRESCALER_DIV1;
  huart2.AdvancedInit.AdvFeatureInit = UART_ADVFEATURE_NO_INIT;
  if (HAL_UART_Init(&huart2) != HAL_OK)
  {
    Error_Handler();
  }
  if (HAL_UARTEx_SetTxFifoThreshold(&huart2, UART_TXFIFO_THRESHOLD_1_8) != HAL_OK)
  {
    Error_Handler();
  }
  if (HAL_UARTEx_SetRxFifoThreshold(&huart2, UART_RXFIFO_THRESHOLD_1_8) != HAL_OK)
  {
    Error_Handler();
  }
  if (HAL_UARTEx_DisableFifoMode(&huart2) != HAL_OK)
  {
    Error_Handler();
  }

}

static void MX_DMA_Init(void)
{

  /* DMA controller clock enable */
  __HAL_RCC_DMA1_CLK_ENABLE();

  /* DMA interrupt init */
  /* DMA1_Stream0_IRQn interrupt configuration */
  HAL_NVIC_SetPriority(DMA1_Stream0_IRQn, 5, 0);
  HAL_NVIC_EnableIRQ(DMA1_Stream0_IRQn);

}

static void MX_GPIO_Init(void)
{
  GPIO_InitTypeDef GPIO_InitStruct = {0};

  /* GPIO Ports Clock Enable */
  __HAL_RCC_GPIOC_CLK_ENABLE();
  __HAL_RCC_GPIOA_CLK_ENABLE();
  __HAL_RCC_GPIOB_CLK_ENABLE();
  __HAL_RCC_GPIOE_CLK_ENABLE();
  __HAL_RCC_GPIOD_CLK_ENABLE();
  __HAL_RCC_GPIOG_CLK_ENABLE();

  /*Configure GPIO pin : IMU_INT_PIN_Pin */
  GPIO_InitStruct.Pin = IMU_INT_PIN_Pin;
  GPIO_InitStruct.Mode = GPIO_MODE_IT_FALLING;
  GPIO_InitStruct.Pull = GPIO_PULLUP;
  HAL_GPIO_Init(IMU_INT_PIN_GPIO_Port, &GPIO_InitStruct);

  /*Configure GPIO pins : PA8 PA11 PA12 */
  GPIO_InitStruct.Pin = GPIO_PIN_8|GPIO_PIN_11|GPIO_PIN_12;
  GPIO_InitStruct.Mode = GPIO_MODE_AF_PP;
  GPIO_InitStruct.Pull = GPIO_NOPULL;
  GPIO_InitStruct.Speed = GPIO_SPEED_FREQ_LOW;
  GPIO_InitStruct.Alternate = GPIO_AF10_OTG1_FS;
  HAL_GPIO_Init(GPIOA, &GPIO_InitStruct);

  /* EXTI interrupt init*/
  HAL_NVIC_SetPriority(EXTI15_10_IRQn, 5, 0);
  HAL_NVIC_EnableIRQ(EXTI15_10_IRQn);

  /* USER CODE BEGIN MX_GPIO_Init_2 */
  // Initialize MD20A direction pins as outputs (default LOW for forward)
  GPIO_InitStruct.Pin = DIR1_Pin | DIR2_Pin | DIR3_Pin;
  GPIO_InitStruct.Mode = GPIO_MODE_OUTPUT_PP;
  GPIO_InitStruct.Pull = GPIO_NOPULL;
  GPIO_InitStruct.Speed = GPIO_SPEED_FREQ_LOW;
  HAL_GPIO_Init(DIR1_GPIO_Port, &GPIO_InitStruct);

  // Initialize Pololu HP MOSFET ON pins as outputs (default LOW)
  GPIO_InitStruct.Pin = MOTOR_ON1_Pin | MOTOR_ON2_Pin | MOTOR_ON3_Pin;
  GPIO_InitStruct.Mode = GPIO_MODE_OUTPUT_PP;
  GPIO_InitStruct.Pull = GPIO_NOPULL;
  GPIO_InitStruct.Speed = GPIO_SPEED_FREQ_LOW;
  HAL_GPIO_Init(GPIOG, &GPIO_InitStruct);

  HAL_GPIO_WritePin(GPIOG, MOTOR_ON1_Pin | MOTOR_ON2_Pin | MOTOR_ON3_Pin, GPIO_PIN_RESET);

  // Set all to forward initially (LOW)
  HAL_GPIO_WritePin(DIR1_GPIO_Port, DIR1_Pin | DIR2_Pin | DIR3_Pin, GPIO_PIN_RESET);

  // Staggered motor ON enable sequence: HIGH with 50ms delay between each
  HAL_GPIO_WritePin(MOTOR_ON1_GPIO_Port, MOTOR_ON1_Pin, GPIO_PIN_SET);
  HAL_Delay(50);
  HAL_GPIO_WritePin(MOTOR_ON2_GPIO_Port, MOTOR_ON2_Pin, GPIO_PIN_SET);
  HAL_Delay(50);
  HAL_GPIO_WritePin(MOTOR_ON3_GPIO_Port, MOTOR_ON3_Pin, GPIO_PIN_SET);
  /* USER CODE END MX_GPIO_Init_2 */
}

/* USER CODE BEGIN 4 */
double yaw_shifter = 0;
static double twopion60 = 2*M_PI/60;
void BSP_PB_Callback(Button_TypeDef Button)
{
	static int on = 0;
	if (on == 0)
	{
		// speed[0] = 3;
		// speed[1] = 0;
		// speed[2] = 0;
    yaw_shifter = 15*twopion60;
		on = 1;
	}
	else if (on == 1)
	{
		// speed[0] = 0;
		// speed[1] = 3;
		// speed[2] = 0;
    yaw_shifter = 30*twopion60;
		on = 2;
	}
	else if (on == 2)
	{
		// speed[0] = 0;
		// speed[1] = 0;
		// speed[2] = 3;
    yaw_shifter = 45*twopion60;
		on = 3;
	}
  else if (on == 3)
	{
		// speed[0] = 0;
		// speed[1] = 0;
		// speed[2] = 0;
    yaw_shifter = 0;
		on = 0;
	}
	/*if (on == 0)
	{
		__HAL_TIM_SET_COMPARE(&htim2, TIM_CHANNEL_2, SLOW);
		on = 1;
	}
	else if (on == 1)
	{
		__HAL_TIM_SET_COMPARE(&htim2, TIM_CHANNEL_2, MED);
		on = 2;
	}
	else if (on == 2)
	{
		__HAL_TIM_SET_COMPARE(&htim2, TIM_CHANNEL_2, MED1);
		on = 3;
	}
	else if (on == 3)
	{
		__HAL_TIM_SET_COMPARE(&htim2, TIM_CHANNEL_2, MED2);
		on = 4;
	}
	else if (on == 4)
	{
		__HAL_TIM_SET_COMPARE(&htim2, TIM_CHANNEL_2, MED3);
		on = 5;
	}
	else if (on == 5)
	{
		__HAL_TIM_SET_COMPARE(&htim2, TIM_CHANNEL_2, MAXf);
		on = 6;
	}
	else if (on == 6)
	{
		__HAL_TIM_SET_COMPARE(&htim2, TIM_CHANNEL_2, NEUTRAL);
		on = 0;
	}*/

	BSP_LED_Toggle(LED_RED);
}
double x[3] = {0},xd[5] = {0},u_out[3] = {0};
double vd[3] = {0};
static volatile int32_t s_enc_delta_raw[3] = {0, 0, 0};

static void enc(double dt, double rpm[3])
{
	int32_t cnt1	 = (int32_t)__HAL_TIM_GET_COUNTER(&htim3);
	int32_t delta1 = cnt1 - CNT_MID;
	__HAL_TIM_SET_COUNTER(&htim3, CNT_MID);

	int32_t cnt2	 = (int32_t)__HAL_TIM_GET_COUNTER(&htim4);
	int32_t delta2 = cnt2 - CNT_MID;
	__HAL_TIM_SET_COUNTER(&htim4, CNT_MID);

	int32_t cnt3	 = (int32_t)__HAL_TIM_GET_COUNTER(&htim8);
	int32_t delta3 = cnt3 - CNT_MID;
	__HAL_TIM_SET_COUNTER(&htim8, CNT_MID);

  s_enc_delta_raw[0] = delta1;
  s_enc_delta_raw[1] = delta2;
  s_enc_delta_raw[2] = delta3;

  static double t_since_edge_s[3] = {0.0, 0.0, 0.0};
  static double rpm_period[3] = {0.0, 0.0, 0.0};
  static double rpm_filt[3] = {0.0, 0.0, 0.0};

  const int32_t delta[3] = {delta1, delta2, delta3};
  const double enc_sign[3] = {ENC_WHEEL1_SIGN, ENC_WHEEL2_SIGN, ENC_WHEEL3_SIGN};
  const double rpm_per_count = 60.0 / (CPR * dt);
  const double pulse_timeout_s = 0.25;
  const double alpha = 0.35;

  for (int i = 0; i < 3; ++i)
  {
    t_since_edge_s[i] += dt;

    const int32_t d = delta[i];
  const double d_signed = enc_sign[i] * (double)d;
  double rpm_window = d_signed * rpm_per_count;
    double rpm_meas = rpm_window;

    if (d != 0)
    {
      const int32_t mag = (d >= 0) ? d : -d;
      if (t_since_edge_s[i] > 0.0)
      {
        rpm_period[i] = (d_signed * 60.0) / (CPR * t_since_edge_s[i]);
      }
      t_since_edge_s[i] = 0.0;

      if (mag <= 1)
      {
        const double blend_period = 0.85;
        rpm_meas = (blend_period * rpm_period[i]) + ((1.0 - blend_period) * rpm_window);
      }
      else
      {
        const double blend_period = 0.35;
        rpm_meas = (blend_period * rpm_period[i]) + ((1.0 - blend_period) * rpm_window);
      }
    }
    else
    {
      if (t_since_edge_s[i] > pulse_timeout_s)
      {
        rpm_period[i] = 0.0;
      }
      rpm_meas = rpm_period[i];
    }

    rpm_filt[i] += alpha * (rpm_meas - rpm_filt[i]);
    rpm[i] = rpm_filt[i];
  }
}

static HAL_StatusTypeDef ReadMotorCurrentAdcRaw(uint16_t adc_raw_out[3])
{
  if (s_motorCurrentDmaStarted == 0u)
  {
    return HAL_ERROR;
  }

  uint32_t accum[3] = {0u, 0u, 0u};
  for (uint16_t i = 0u; i < MOTOR_CURRENT_DMA_SAMPLES; i += 3u)
  {
    accum[0] += s_motorCurrentAdcDmaBuf[i + 0u];
    accum[1] += s_motorCurrentAdcDmaBuf[i + 1u];
    accum[2] += s_motorCurrentAdcDmaBuf[i + 2u];
  }

  adc_raw_out[0] = (uint16_t)(accum[0] / MOTOR_CURRENT_DMA_SEQUENCES);
  adc_raw_out[1] = (uint16_t)(accum[1] / MOTOR_CURRENT_DMA_SEQUENCES);
  adc_raw_out[2] = (uint16_t)(accum[2] / MOTOR_CURRENT_DMA_SEQUENCES);
  return HAL_OK;
}

static const float kMotorCurrentAdcVref = 3.3f;
static const float kMotorCurrentAdcFullScale = 4095.0f;
static const float kMotorCurrentSensitivityVPerA[3] = {0.0264f, 0.0264f, 0.0264f};
static float s_motorCurrentOffsetRaw[3] = {2048.0f, 2048.0f, 2048.0f};
static float s_motorCurrentBiasA[3] = {0.0f, 0.0f, 0.0f};

static void CalibrateMotorCurrentOffset(uint16_t sample_count)
{
  if (sample_count == 0u)
  {
    return;
  }

  uint32_t accum[3] = {0u, 0u, 0u};
  uint16_t adc_raw[3] = {0u, 0u, 0u};
  uint16_t valid_samples = 0u;

  for (uint16_t i = 0u; i < sample_count; ++i)
  {
    if (ReadMotorCurrentAdcRaw(adc_raw) == HAL_OK)
    {
      accum[0] += adc_raw[0];
      accum[1] += adc_raw[1];
      accum[2] += adc_raw[2];
      ++valid_samples;
    }

    vTaskDelay(pdMS_TO_TICKS(2));
  }

  if (valid_samples > 0u)
  {
    s_motorCurrentOffsetRaw[0] = (float)accum[0] / (float)valid_samples;
    s_motorCurrentOffsetRaw[1] = (float)accum[1] / (float)valid_samples;
    s_motorCurrentOffsetRaw[2] = (float)accum[2] / (float)valid_samples;
  }
}

static float MotorCurrentRawToAmps(uint16_t raw, uint8_t channel_index)
{
  uint8_t idx = channel_index;
  if (idx > 2u)
  {
    idx = 2u;
  }

  const float adc_lsb_v = kMotorCurrentAdcVref / kMotorCurrentAdcFullScale;
  const float delta_v = ((float)raw - s_motorCurrentOffsetRaw[idx]) * adc_lsb_v;
  return (delta_v / kMotorCurrentSensitivityVPerA[idx]) - s_motorCurrentBiasA[idx];
}

static void CalibrateMotorCurrentBiasA(uint16_t sample_count)
{
  if (sample_count == 0u)
  {
    return;
  }

  float accum_a[3] = {0.0f, 0.0f, 0.0f};
  uint16_t adc_raw[3] = {0u, 0u, 0u};
  uint16_t valid_samples = 0u;

  for (uint16_t i = 0u; i < sample_count; ++i)
  {
    if (ReadMotorCurrentAdcRaw(adc_raw) == HAL_OK)
    {
      const float adc_lsb_v = kMotorCurrentAdcVref / kMotorCurrentAdcFullScale;
      const float delta_v0 = ((float)adc_raw[0] - s_motorCurrentOffsetRaw[0]) * adc_lsb_v;
      const float delta_v1 = ((float)adc_raw[1] - s_motorCurrentOffsetRaw[1]) * adc_lsb_v;
      const float delta_v2 = ((float)adc_raw[2] - s_motorCurrentOffsetRaw[2]) * adc_lsb_v;

      accum_a[0] += (delta_v0 / kMotorCurrentSensitivityVPerA[0]);
      accum_a[1] += (delta_v1 / kMotorCurrentSensitivityVPerA[1]);
      accum_a[2] += (delta_v2 / kMotorCurrentSensitivityVPerA[2]);
      ++valid_samples;
    }

    vTaskDelay(pdMS_TO_TICKS(2));
  }

  if (valid_samples > 0u)
  {
    s_motorCurrentBiasA[0] = accum_a[0] / (float)valid_samples;
    s_motorCurrentBiasA[1] = accum_a[1] / (float)valid_samples;
    s_motorCurrentBiasA[2] = accum_a[2] / (float)valid_samples;
  }
}

#include "math.h"

static double wrap_to_pi(double a)
{
  while (a > M_PI) { a -= 2.0 * M_PI; }
  while (a < -M_PI) { a += 2.0 * M_PI; }
  return a;
}

static double lerp(double a, double b, double t)
{
  return a + (b - a) * t;
}

static double lerp_angle(double a, double b, double t)
{
  const double da = wrap_to_pi(b - a);
  return wrap_to_pi(a + (da * t));
}

double yaw = 0,yawrate = 0,ax = 0,ay = 0,az = 0;
double battery_v = 24;
void remote(void *argument)
{
	int tick = 10;
  const uint32_t trajDeadmanTimeoutMs = 700u;
  const TickType_t period = pdMS_TO_TICKS(tick); // 100 Hz
	const TickType_t wheelStallHoldTime = pdMS_TO_TICKS(250);
	const TickType_t yawKickTime = pdMS_TO_TICKS(520);
	const double wheelStallRpmThreshold = 3.0;
  const double requestedMotionThreshold = 1e-3;
  const double pointFocusDistanceM = 0.5;
	TickType_t lastWakeTime = xTaskGetTickCount();
  const TickType_t posePeriod = pdMS_TO_TICKS(100); // 10 Hz pose heartbeat
  TickType_t lastPoseTick = xTaskGetTickCount();
  const TickType_t batteryPeriod = pdMS_TO_TICKS(60000);
  TickType_t lastBatteryTick = xTaskGetTickCount();
  TickType_t wheelStallStartTick = 0;
  TickType_t yawKickEndTick = 0;
  uint8_t yawKickActive = 0u;
  double yawrateBeforeKick = 0.0;
  uint8_t last_point_focus_mode = 0u;
  uint8_t last_face_forward_mode = 0u;
  uint8_t point_focus_target_valid = 0u;
  double point_focus_target_x_m = 0.0;
  double point_focus_target_y_m = 0.0;
  double face_forward_yaw_des = 0.0;
  uint16_t current_adc_raw[3] = {0u, 0u, 0u};
  float current_a[3] = {0.0f, 0.0f, 0.0f};

    const float dt = (float)(period * portTICK_PERIOD_MS) * 1e-3f;

    //CMD_Send("Remote task started\n");
    CalibrateMotorCurrentOffset(200u);
    CalibrateMotorCurrentBiasA(1000u);
  uint16_t current_sample_count = 0u;
  float current_sum_a[3] = {0.0f, 0.0f, 0.0f};
  // Boot in autonomous blank-map mode (traj 3).
  UDP_Client_InvalidateLatestTraj();
  traj_mode = 1u;
  UDP_Client_RequestCmd(CMD_START_TRAJ_LOCAL);
	for (;;)
	{
	    vTaskDelayUntil(&lastWakeTime, period);

	    static double rpm[3] = {0};

	    // Get IMU data with linear acceleration (gravity compensated)
	    BNO_RVC_UpdateMain(&yaw, &yawrate, &ax, &ay, &az);

	    enc(dt,rpm);
      /*rpm[0] = speed[0]*60/(2*M_PI);
      rpm[1] = speed[1]*60/(2*M_PI);
      rpm[2] = speed[2]*60/(2*M_PI);*/

      TickType_t nowTick = xTaskGetTickCount();
      if ((nowTick - lastBatteryTick) >= batteryPeriod)
      {
        battery_v = (double)BatteryMonitor_ReadVoltage_V();
        const double battery_scaled_max_rpm = (battery_v / 24.8) * SATURN5303_NO_LOAD_RPM;
        PWM_SetMaxRpmLimit(battery_scaled_max_rpm);
        lastBatteryTick = nowTick;
        //printf(" Battery: %.2f V \n",battery_v);
        char battery_msg[48];
        (void)snprintf(battery_msg, sizeof(battery_msg), "Battery: %.2f V\r\n", battery_v);
        CMD_Send(battery_msg);
        if (battery_v < 21)
        {
          CMD_Send("Charge The Bot !!!\n");
        }
      }

      if (ReadMotorCurrentAdcRaw(current_adc_raw) == HAL_OK)
      {
        current_a[0] = MotorCurrentRawToAmps(current_adc_raw[0], 0u);
        current_a[1] = MotorCurrentRawToAmps(current_adc_raw[1], 1u);
        current_a[2] = MotorCurrentRawToAmps(current_adc_raw[2], 2u);
      }

      static uint8_t last_traj_mode = 0u;
      const uint8_t cur_traj_mode = traj_mode;
      const uint8_t cur_point_focus_mode = point_focus_mode;
      const uint8_t cur_face_forward_mode = face_forward_mode;

      if (yawKickActive)
      {
        if (!yaw_kick_enabled)
        {
          yawrated = yawrateBeforeKick;
          yawKickActive = 0u;
          wheelStallStartTick = 0;
        }
        else if ((nowTick - yawKickEndTick) < ((TickType_t)0xFFFFFFFF / 2u))
        {
          yawrated = yawrateBeforeKick;
          yawKickActive = 0u;
          wheelStallStartTick = 0;
        }
        else
        {
          yawrated = 1.0;
        }
      }

      const double yaw_rad = yaw * pion180;
      /*static int cunttter = 0;
      if (cunttter++ > 50)
      {
        cunttter = 0;
        printf("%.2f\n", yaw);
      } */
      // Rising edge: enter trajectory-follow mode
      if ((last_traj_mode == 0u) && (cur_traj_mode == 1u))
      {
          // Preserve estimator state when switching/reenabling trajectories.
          // Only clear the desired vector to avoid carrying stale commands.
          for (int i = 0; i < 5; i++) { xd[i] = 0.0; }
      }
      last_traj_mode = cur_traj_mode;

      if (yaw_kick_enabled && (cur_traj_mode == 0u) && (cur_point_focus_mode == 0u) && !wheel_test_mode && !pwm_test_mode && !yawKickActive)
      {
        const uint8_t moving =
          (fabs(vxd) > requestedMotionThreshold) ||
          (fabs(vyd) > requestedMotionThreshold);

        const uint8_t wheel0Slow = (fabs(rpm[0]) <= wheelStallRpmThreshold);
        const uint8_t wheel1Slow = (fabs(rpm[1]) <= wheelStallRpmThreshold);
        const uint8_t wheel2Slow = (fabs(rpm[2]) <= wheelStallRpmThreshold);
        const uint8_t slowWheelCount =
            (uint8_t)wheel0Slow + (uint8_t)wheel1Slow + (uint8_t)wheel2Slow;
        const uint8_t exactlyOneWheelSlow = (slowWheelCount == 1u);

        if (moving && exactlyOneWheelSlow)
        {
          if (wheelStallStartTick == 0)
          {
            wheelStallStartTick = nowTick;
          }
          else if ((nowTick - wheelStallStartTick) >= wheelStallHoldTime)
          {
            yawrateBeforeKick = yawrated;
            yawrated = 1.5;
            yawKickEndTick = nowTick + yawKickTime;
            yawKickActive = 1u;
            wheelStallStartTick = 0;
          }
        }
        else
        {
          wheelStallStartTick = 0;
        }
      }
      else if ((cur_traj_mode != 0u) || wheel_test_mode || pwm_test_mode)
      {
        wheelStallStartTick = 0;
      }

      // Always run the state estimator so pose is available in both modes.
      // Convert measured wheel speeds (rpm) to rad/s for estimator.
      double w_rad_s[3];
      w_rad_s[0] = rpm[0] * twopion60;
      w_rad_s[1] = rpm[1] * twopion60;
      w_rad_s[2] = rpm[2] * twopion60;
      StateEstimator_Update(w_rad_s, (double)dt, yaw_rad, ax, ay, x);

      if ((last_point_focus_mode == 0u) && (cur_point_focus_mode == 1u))
      {
        point_focus_target_x_m = x[0] + (pointFocusDistanceM * cos(x[2]));
        point_focus_target_y_m = x[1] + (pointFocusDistanceM * sin(x[2]));
        point_focus_target_valid = 1u;
      }
      else if (cur_point_focus_mode == 0u)
      {
        point_focus_target_valid = 0u;
      }
      last_point_focus_mode = cur_point_focus_mode;

      if ((last_face_forward_mode == 0u) && (cur_face_forward_mode == 1u))
      {
        face_forward_yaw_des = x[2];
      }
      last_face_forward_mode = cur_face_forward_mode;

      if (cur_face_forward_mode)
      {
        if ((fabs(vxd) > 1e-6) || (fabs(vyd) > 1e-6))
        {
          face_forward_yaw_des = atan2(vyd, vxd);
        }
      }

      double point_focus_yaw_des = x[2];
      if (cur_point_focus_mode && point_focus_target_valid)
      {
        const double dx = point_focus_target_x_m - x[0];
        const double dy = point_focus_target_y_m - x[1];
        if ((fabs(dx) > 1e-6) || (fabs(dy) > 1e-6))
        {
          point_focus_yaw_des = atan2(dy, dx);
        }
      }

      /*{
        static int slip_dbg_counter = 0;
        if (++slip_dbg_counter >= 50) // ~0.5 s at 100 Hz
        {
          slip_dbg_counter = 0;
          double slip_dbg[6] = {0.0, 0.0, 0.0, 0.0, 0.0, 0.0};
          double tune_dbg[6] = {0.0, 0.0, 0.0, 0.0, 0.0, 0.0};
          double fuse_dbg[6] = {0.0, 0.0, 0.0, 0.0, 0.0, 0.0};
          StateEstimator_GetSlipDebug(slip_dbg);
          StateEstimator_GetTuningDebug(tune_dbg);
          StateEstimator_GetFuseDebug(fuse_dbg);
               printf("SLIP sr=%.2f we=%.2f wi=%.2f in=%.2f b=(%.2f,%.2f) a=(%.2f,%.2f) p=(%.2f,%.2f,%.2f)\n",
                 slip_dbg[0],
                 slip_dbg[1],
                 slip_dbg[2],
                 slip_dbg[3],
                 slip_dbg[4],
                 slip_dbg[5],
                 ax,
               ay,
               x[0],
               x[1],
               x[2]);
               printf("EST c=%.2f db=%.2f ve=%.2f st=%u sb=%u tt=%.2f\n",
                 tune_dbg[0],
                 tune_dbg[1],
                 tune_dbg[2],
                 (unsigned int)tune_dbg[3],
                 (unsigned int)tune_dbg[4],
                 tune_dbg[5]);
               printf("FUSE we=%.2f wi=%.2f ve=(%.2f,%.2f) vf=(%.2f,%.2f)\n",
               fuse_dbg[0],
               fuse_dbg[1],
               fuse_dbg[2],
               fuse_dbg[3],
               fuse_dbg[4],
               fuse_dbg[5]);
        }
      }*/

        if (pwm_test_mode)
        {
          speed[0] = 0.0;
          speed[1] = 0.0;
          speed[2] = 0.0;
          static int cunttter = 0;
          if (cunttter++ > 50)
          {
              cunttter = 0;
              printf("%.1f %.1f %.1f\n", rpm[0], rpm[1], rpm[2]);
          }
        }
        if (wheel_test_mode)
        {
          int idx = (wheel_test_index >= 0 && wheel_test_index < 3) ? wheel_test_index : 0;

          speed[0] = 0.0;
          speed[1] = 0.0;
          speed[2] = 0.0;
          speed[idx] = (WHEEL_TEST_CMD_SIGN * wheel_test_target_rpm) * twopion60;
          static int cunttter = 0;
          if (cunttter++ > 50)
          {
              cunttter = 0;
              printf("%.1f %.1f %.1f\n", rpm[0], rpm[1], rpm[2]);
          }
        }
        else if (cur_traj_mode == 0u)
      {
          /*static int cuunttter = 0;
          if (cuunttter++ > 50)
          {
              cuunttter = 0;
              printf("%.2f %.2f %.2f\n", x[0], x[1], x[2]);
          }*/
          // =====================
          // traj 0: remote/manual
          // =====================
          if (cur_point_focus_mode)
          {
            // Keep manual translation commands, but close yaw to the locked world point.
            xd[0] = x[0];
            xd[1] = x[1];
            xd[2] = point_focus_yaw_des;
            xd[3] = vxd;
            xd[4] = vyd;
            Controller_Step(x, xd, vd, 1, dt);
          }
          else if (cur_face_forward_mode)
          {
            // Keep manual translation commands and align heading to command direction.
            xd[0] = x[0];
            xd[1] = x[1];
            xd[2] = face_forward_yaw_des;
            xd[3] = vxd;
            xd[4] = vyd;
            Controller_Step(x, xd, vd, 1, dt);
          }
          else
          {
            vd[0] = vxd;
            vd[1] = vyd;
            vd[2] = yawrated;
            Controller_Step(x, xd, vd, 0, dt);  // selector=0 for velocity control
          }
      }
      else
      {
          // =========================
          // traj 1: follow Pi5 traj
          // =========================
          // Pull latest trajectory (if any)
          typedef struct __attribute__((packed))
          {
              float x;
              float y;
              float yaw;
              float vx;
              float vy;
          } Pi5TrajectoryKnot;

          static Pi5TrajectoryKnot knots[UDP_MAX_TRAJ_KNOTS];
          uint16_t n_knots = 0;
          float knot_dt = 0.0f;
          uint16_t traj_flags = 0;
          uint32_t traj_t0_ms = 0;
          uint32_t traj_seq = 0;

          bool have_traj = UDP_Client_CopyLatestTraj(knots,
                                                    sizeof(knots),
                                                    &n_knots,
                                                    &knot_dt,
                                                    &traj_flags,
                                                    &traj_t0_ms,
                                                    &traj_seq);

            uint32_t traj_age_ms = UDP_Client_GetLatestTrajAgeMs();
            if (traj_age_ms > trajDeadmanTimeoutMs)
            {
              have_traj = false;
            }

          // Default to pose-hold with zero feedforward so stale/missing traj commands a stop.
          xd[0] = x[0];
          xd[1] = x[1];
          xd[2] = x[2];
          xd[3] = 0.0;
          xd[4] = 0.0;

          if (have_traj && (n_knots > 0u) && (knot_dt > 0.0f))
          {
              uint32_t now_ms = HAL_GetTick();
              float elapsed_s = 0.0f;
              if (now_ms >= traj_t0_ms)
              {
                elapsed_s = ((float)(now_ms - traj_t0_ms)) * 1e-3f;
              }

              // Interpolate by time to avoid 100 Hz control jitter from nearest-knot sampling.
              float sample = elapsed_s / knot_dt;
              uint32_t idx0 = (uint32_t)sample;
              if (idx0 >= (uint32_t)n_knots)
              {
                idx0 = (uint32_t)n_knots - 1u;
              }

              uint32_t idx1 = idx0 + 1u;
              if (idx1 >= (uint32_t)n_knots)
              {
                idx1 = idx0;
              }

              float alpha = sample - (float)idx0;
              if (alpha < 0.0f) { alpha = 0.0f; }
              if (alpha > 1.0f) { alpha = 1.0f; }

              const Pi5TrajectoryKnot *k0 = &knots[idx0];
              const Pi5TrajectoryKnot *k1 = &knots[idx1];

              xd[0] = lerp((double)k0->x, (double)k1->x, (double)alpha);
              xd[1] = lerp((double)k0->y, (double)k1->y, (double)alpha);
              xd[2] = lerp_angle((double)k0->yaw, (double)k1->yaw, (double)alpha);

              // Use feedforward velocities directly from Pi5 trajectory planner
              xd[3] = lerp((double)k0->vx, (double)k1->vx, (double)alpha);
              xd[4] = lerp((double)k0->vy, (double)k1->vy, (double)alpha);
          }

          if (cur_point_focus_mode)
          {
            xd[2] = point_focus_yaw_des;
          }

          // Use trajectory mode selector=1
          Controller_Step(x, xd, vd, 1, dt);
      }

      if (wheel_test_mode || pwm_test_mode || (cur_traj_mode == 0u))
      {
        /*current_sum_a[0] += current_a[0];
        current_sum_a[1] += current_a[1];
        current_sum_a[2] += current_a[2];
        current_sample_count++;

        if (current_sample_count >= 50u)
        {
          char current_msg[96];
          (void)snprintf(current_msg,
                         sizeof(current_msg),
                         "%.1f %.1f %.1f\r\n",
                         current_sum_a[0] / (float)current_sample_count,
                         current_sum_a[1] / (float)current_sample_count,
                         current_sum_a[2] / (float)current_sample_count);
          CMD_Send(current_msg);
          current_sample_count = 0u;
          current_sum_a[0] = 0.0f;
          current_sum_a[1] = 0.0f;
          current_sum_a[2] = 0.0f;
        }*/
      }
      else
      {
        current_sample_count = 0u;
        current_sum_a[0] = 0.0f;
        current_sum_a[1] = 0.0f;
        current_sum_a[2] = 0.0f;
      }

      if (pwm_test_mode)
      {
        const uint32_t ch[3] = { TIM_CHANNEL_1, TIM_CHANNEL_2, TIM_CHANNEL_3 };
        GPIO_TypeDef *dir_ports[3] = { DIR1_GPIO_Port, DIR2_GPIO_Port, DIR3_GPIO_Port };
        uint16_t dir_pins[3] = { DIR1_Pin, DIR2_Pin, DIR3_Pin };

        for (int i = 0; i < 3; ++i)
        {
          double ratio = pwm_test_ratio[i];
          if (ratio > 1.0) ratio = 1.0;
          if (ratio < -1.0) ratio = -1.0;

          HAL_GPIO_WritePin(dir_ports[i], dir_pins[i], (ratio < 0.0) ? GPIO_PIN_SET : GPIO_PIN_RESET);

          double duty = fabs(ratio) * (double)PWM_RANGE;
          if (duty > (double)PWM_MAX) duty = (double)PWM_MAX;
          __HAL_TIM_SET_COMPARE(&htim2, ch[i], (uint32_t)duty);
        }
      }
      else
      {
        PWM(rpm,dt);
      }

      // Push pose to Pi5 at 10 Hz to align pose cadence with Pi LiDAR update rate
      if ((nowTick - lastPoseTick) >= posePeriod)
      {
    	    PosePayload pose;
            double vel_body[3] = {0.0, 0.0, 0.0};
    	    pose.pose_t_ms = HAL_GetTick();
          // Publish estimated pose in both manual and trajectory modes.
          pose.x = (float)x[0];
          pose.y = (float)x[1];
          pose.yaw = (float)x[2];
          StateEstimator_GetBodyVelocity(vel_body);
          pose.vx = (float)vel_body[0];
          pose.vy = (float)vel_body[1];
          pose.wz = (float)vel_body[2];

    	    queue_pose(&pose);

          /*char imu_msg[96];
          (void)snprintf(imu_msg,sizeof(imu_msg),"%.1f %.1f, %.1f %.1f\r\n",x[0],xd[0],x[1],xd[1]);
          CMD_Send(imu_msg);*/
		      //UDP_Client_SendZeroPose();
    	    lastPoseTick = nowTick;
      }

	    //if (counter++%100 == 0)
	    {
	    	//printf("%.2f %.2f %.2f\n", ax,ay,az);
	    }

	}
}

void control(void *argument)
{
	//uint32_t counter = 0;
    const TickType_t period = pdMS_TO_TICKS(10);   // 100 Hz
    TickType_t lastWakeTime = xTaskGetTickCount(); // init once
	for(;;)
	{
		//uint32_t t_last = HAL_GetTick();

		//Controller_Step(x,xd,u_out,vd,1);

		//uint32_t c_t = HAL_GetTick() - t_last;
		//printf("%lu\n",c_t);

		//if (counter++%10 == 0)
		{
			//printf("%.4f %.4f %.4f\n",u_out[0],u_out[1],u_out[2]);
		}

		vTaskDelayUntil(&lastWakeTime, period);
	}
}

int _write(int file, char *ptr, int len) {
    HAL_UART_Transmit(&hcom_uart[COM1], (uint8_t*)ptr, len, 50);
    return len;
}
/* USER CODE END 4 */

void StartDefaultTask(void *argument)
{
  /* init code for LWIP */
  MX_LWIP_Init();
  /* USER CODE BEGIN 5 */
   for(;;)
  {

	  BSP_LED_Toggle(LED_GREEN);
	  osDelay(150);
    BSP_LED_Toggle(LED_YELLOW);
    osDelay(150);
    BSP_LED_Toggle(LED_RED);
    osDelay(150);
  }
  /* USER CODE END 5 */
}

void Error_Handler(void)
{
  __disable_irq();
  while (1)
  {
  }
}

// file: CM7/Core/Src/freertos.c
/* USER CODE BEGIN Header */
/**
  ******************************************************************************
  * File Name          : freertos.c
  * Description        : Code for freertos applications
  ******************************************************************************
  * @attention
  *
  * Copyright (c) 2025 STMicroelectronics.
  * All rights reserved.
  *
  * This software is licensed under terms that can be found in the LICENSE file
  * in the root directory of this software component.
  * If no LICENSE file comes with this software, it is provided AS-IS.
  *
  ******************************************************************************
  */
/* USER CODE END Header */

#include "FreeRTOS.h"
#include "task.h"
#include "main.h"

/* USER CODE BEGIN Includes */
#include <stdio.h>
/* USER CODE END Includes */

/* USER CODE BEGIN Application */

/**
  * @brief  Application Malloc failed hook
  * @param  None
  * @retval None
  */
void vApplicationMallocFailedHook(void)
{
  printf("\r\n\r\n*** MALLOC FAILED ***\r\n");
  printf("FreeRTOS heap exhausted!\r\n");
  printf("Current heap size: %lu bytes\r\n", (unsigned long)configTOTAL_HEAP_SIZE);
  printf("Increase configTOTAL_HEAP_SIZE in FreeRTOSConfig.h\r\n");
  printf("System halted.\r\n\r\n");
  taskDISABLE_INTERRUPTS();
  for(;;);
}

/**
  * @brief  Application stack overflow hook
  * @param  xTask: Task handle
  * @param  pcTaskName: Task name
  * @retval None
  */
void vApplicationStackOverflowHook(TaskHandle_t xTask, char *pcTaskName)
{
  (void)xTask;
  printf("\r\n\r\n*** STACK OVERFLOW ***\r\n");
  printf("Task: %s\r\n", pcTaskName);
  printf("Increase stack size for this task\r\n");
  printf("System halted.\r\n\r\n");
  taskDISABLE_INTERRUPTS();
  for(;;);
}

/* USER CODE END Application */
